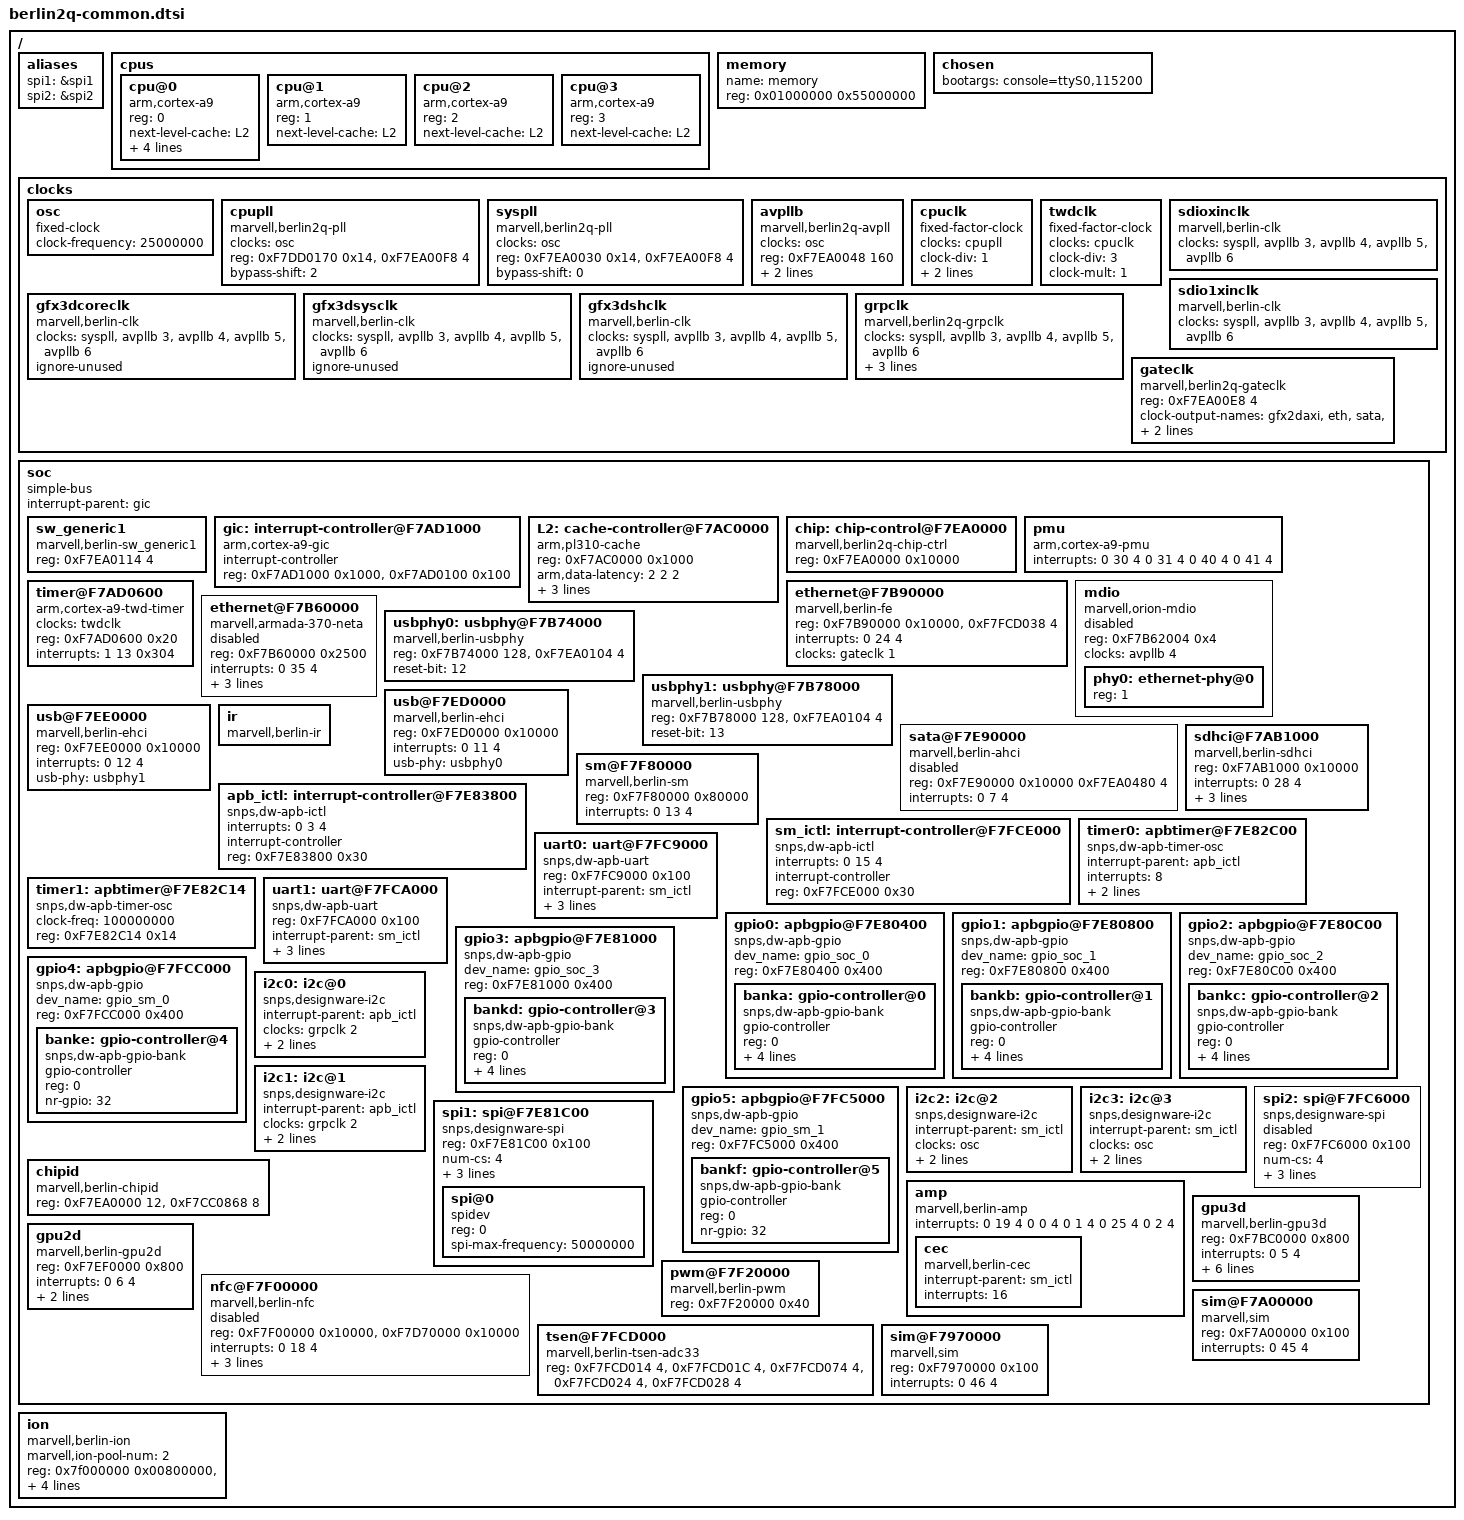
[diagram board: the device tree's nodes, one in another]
/*
 * MARVELL BERLIN2Q SoC device tree source
 *
 * Author:	Jisheng Zhang <jszhang@marvell.com>
 * Copyright (c) 2013 Marvell Technology Group Ltd.
 *		http://www.marvell.com
 *
 * MARVELL BERLIN2Q SoC device nodes are listed in this file.
 * BERLIN2Q based board files can include this file and provide
 * values for board specfic bindings.
 *
 * Note: This file does not include device nodes for all the controllers in
 * BERLIN2Q SoC. As device tree coverage for BERLIN2Q increases,
 * additional nodes can be added to this file.
 *
 * This program is free software; you can redistribute it and/or modify
 * it under the terms of the GNU General Public License version 2 as
 * published by the Free Software Foundation.
*/

/include/ "skeleton.dtsi"

/ {
	aliases {
		spi1 = &spi1;
		spi2 = &spi2;
	};

	cpus {
		#address-cells = <1>;
		#size-cells = <0>;

		cpu@0 {
			device_type = "cpu";
			compatible = "arm,cortex-a9";
			reg = <0>;
			next-level-cache = <&L2>;
			operating-points = <
				/* kHz    uV */
				1200000 1200000
				1000000 1200000
				800000  1200000
				600000  1200000
			>;
			clock-latency = <100000>;
			clocks = <&cpuclk>;
		};

		cpu@1 {
			device_type = "cpu";
			compatible = "arm,cortex-a9";
			reg = <1>;
			next-level-cache = <&L2>;
		};

		cpu@2 {
			device_type = "cpu";
			compatible = "arm,cortex-a9";
			reg = <2>;
			next-level-cache = <&L2>;
		};

		cpu@3 {
			device_type = "cpu";
			compatible = "arm,cortex-a9";
			reg = <3>;
			next-level-cache = <&L2>;
		};
	};

	memory {
		name = "memory";
		device_type = "memory";
		reg = <0x01000000 0x55000000>;
	};

	chosen {
		bootargs = "console=ttyS0,115200";
	};

	clocks {
		#address-cells = <1>;
		#size-cells = <1>;
		ranges;

		osc: osc {
			compatible = "fixed-clock";
			#clock-cells = <0>;
			clock-frequency = <25000000>;
		};

		cpupll: cpupll {
			compatible = "marvell,berlin2q-pll";
			clocks = <&osc>;
			#clock-cells = <0>;
			reg = <0xF7DD0170 0x14>, <0xF7EA00F8 4>;
			bypass-shift = /bits/ 8 <2>;
		};

		syspll: syspll {
			compatible = "marvell,berlin2q-pll";
			clocks = <&osc>;
			#clock-cells = <0>;
			reg = <0xF7EA0030 0x14>, <0xF7EA00F8 4>;
			bypass-shift = /bits/ 8 <0>;
		};

		avpllb: avpllb {
			compatible = "marvell,berlin2q-avpll";
			clocks = <&osc>;
			#clock-cells = <1>;
			reg = <0xF7EA0048 160>;
			clock-output-names = "avpllb1", "avpllb2", "avpllb3", "avpllb4", "avpllb5", "avpllb6", "avpllb7";
		};

		cpuclk: cpuclk {
			compatible = "fixed-factor-clock";
			clocks = <&cpupll>;
			#clock-cells = <0>;
			clock-div = <1>;
			clock-mult = <1>;
			set-rate-parent;
		};

		twdclk: twdclk {
			compatible = "fixed-factor-clock";
			clocks = <&cpuclk>;
			#clock-cells = <0>;
			clock-div = <3>;
			clock-mult = <1>;
		};

		sdioxinclk: sdioxinclk {
			compatible = "marvell,berlin-clk";
			clocks = <&syspll>, <&avpllb 3>, <&avpllb 4>, <&avpllb 5>, <&avpllb 6>;
			#clock-cells = <0>;
		};

		sdio1xinclk: sdio1xinclk {
			compatible = "marvell,berlin-clk";
			clocks = <&syspll>, <&avpllb 3>, <&avpllb 4>, <&avpllb 5>, <&avpllb 6>;
			#clock-cells = <0>;
		};

		gfx3dcoreclk: gfx3dcoreclk {
			compatible = "marvell,berlin-clk";
			clocks = <&syspll>, <&avpllb 3>, <&avpllb 4>, <&avpllb 5>, <&avpllb 6>;
			#clock-cells = <0>;
			ignore-unused;
		};

		gfx3dsysclk: gfx3dsysclk {
			compatible = "marvell,berlin-clk";
			clocks = <&syspll>, <&avpllb 3>, <&avpllb 4>, <&avpllb 5>, <&avpllb 6>;
			#clock-cells = <0>;
			ignore-unused;
		};

		gfx3dshclk: gfx3dshclk {
			compatible = "marvell,berlin-clk";
			clocks = <&syspll>, <&avpllb 3>, <&avpllb 4>, <&avpllb 5>, <&avpllb 6>;
			#clock-cells = <0>;
			ignore-unused;
		};

		grpclk: grpclk {
			compatible = "marvell,berlin2q-grpclk";
			clocks = <&syspll>, <&avpllb 3>, <&avpllb 4>, <&avpllb 5>, <&avpllb 6>;
			#clock-cells = <1>;
			reg = <0xF7EA00F8 4>, <0xF7EA00EC 12>, <0xF7EA00E8 4>;
			clock-output-names = "sys", "drmfigo", "cfg", "gfx2d", "zsp", "perif", "pcube", "vscope", "nfcecc", "app";
		};

		gateclk: gateclk {
			compatible = "marvell,berlin2q-gateclk";
			#clock-cells = <1>;
			reg = <0xF7EA00E8 4>;
			clock-output-names = "gfx2daxi", "eth", "sata", "ahbapb", "usb0", "usb1", "usb2", "usb3", "pbridge", "sdio", "nfc", "pcie", "geth";
		};
	};

	soc {
		#address-cells = <1>;
		#size-cells = <1>;
		compatible = "simple-bus";
		interrupt-parent = <&gic>;
		ranges;

		sw_generic1 {
			compatible = "marvell,berlin-sw_generic1";
			reg = <0xF7EA0114 4>;
		};

		gic:interrupt-controller@F7AD1000 {
			compatible = "arm,cortex-a9-gic";
			#interrupt-cells = <3>;
			interrupt-controller;
			reg = <0xF7AD1000 0x1000>, <0xF7AD0100 0x100>;
		};

		L2: cache-controller@F7AC0000 {
			compatible = "arm,pl310-cache";
			reg = <0xF7AC0000 0x1000>;
			arm,data-latency = <2 2 2>;
			arm,tag-latency = <2 2 2>;
			arm,prefetch-ctrl = <0x70000007>;
			arm,pwr-ctrl = <0x3>;
		};

		chip: chip-control@F7EA0000 {
			compatible = "marvell,berlin2q-chip-ctrl";
			reg = <0xF7EA0000 0x10000>;
			#reset-cells = <3>;
		};

		pmu {
			compatible = "arm,cortex-a9-pmu";
			interrupts = <0 30 4  0 31 4  0 40 4  0 41 4>;
		};

		timer@F7AD0600 {
			compatible = "arm,cortex-a9-twd-timer";
			clocks = <&twdclk>;
			reg = <0xF7AD0600 0x20>;
			interrupts = <1 13 0x304>;
		};

		ethernet@F7B90000 {
			compatible = "marvell,berlin-fe";
			reg = <0xF7B90000 0x10000>,
			      <0xF7FCD038 4>;
			interrupts = <0 24 4>;
			clocks = <&gateclk 1>;
		};

		mdio {
			#address-cells = <1>;
			#size-cells = <0>;
			compatible = "marvell,orion-mdio";
			reg = <0xF7B62004 0x4>;
			status = "disabled";
			clocks = <&avpllb 4>;
			phy0: ethernet-phy@0 {
				reg = <1>;
			};
		};

		ethernet@F7B60000 {
			compatible = "marvell,armada-370-neta";
			reg = <0xF7B60000 0x2500>;
			interrupts = <0 35 4>;
			clocks = <&avpllb 4>;
			status = "disabled";
			phy = <&phy0>;
			phy-mode = "rgmii-id";
		};

		usbphy0: usbphy@F7B74000 {
			compatible = "marvell,berlin-usbphy";
			reg = <0xF7B74000 128>, <0xF7EA0104 4>;
			reset-bit = <12>;
		};

		usbphy1: usbphy@F7B78000 {
			compatible = "marvell,berlin-usbphy";
			reg = <0xF7B78000 128>, <0xF7EA0104 4>;
			reset-bit = <13>;
		};

		usb@F7ED0000 {
			compatible = "marvell,berlin-ehci";
			reg = <0xF7ED0000 0x10000>;
			interrupts = <0 11 4>;
			usb-phy = <&usbphy0>;
		};

		usb@F7EE0000 {
			compatible = "marvell,berlin-ehci";
			reg = <0xF7EE0000 0x10000>;
			interrupts = <0 12 4>;
			usb-phy = <&usbphy1>;
		};

		sata@F7E90000 {
			compatible = "marvell,berlin-ahci";
			reg = <0xF7E90000 0x10000 0xF7EA0480 4>;
			interrupts = <0 7 4>;
			status = "disabled";
		};

		sdhci@F7AB1000 {
			compatible = "marvell,berlin-sdhci";
			reg = <0xF7AB1000 0x10000>;
			interrupts = <0 28 4>;
			clocks = <&grpclk 8>;
			marvell,card-wired;
			marvell,8bit-data;
		};

		sm@F7F80000 {
			compatible = "marvell,berlin-sm";
			reg = <0xF7F80000 0x80000>;
			interrupts = <0 13 4>;
		};

		ir {
			compatible = "marvell,berlin-ir";
		};

		apb_ictl: interrupt-controller@F7E83800 {
			compatible = "snps,dw-apb-ictl";
			interrupts = <0 3 4>;
			interrupt-controller;
			#interrupt-cells = <1>;
			reg = <0xF7E83800 0x30>;
		};

		sm_ictl: interrupt-controller@F7FCE000 {
			compatible = "snps,dw-apb-ictl";
			interrupts = <0 15 4>;
			interrupt-controller;
			#interrupt-cells = <1>;
			reg = <0xF7FCE000 0x30>;
		};

		timer0: apbtimer@F7E82C00 {
			compatible = "snps,dw-apb-timer-osc";
			interrupt-parent = <&apb_ictl>;
			interrupts = <8>;
			clock-freq = <100000000>;
			reg = <0xF7E82C00 0x14>;
		};

		timer1: apbtimer@F7E82C14 {
			compatible = "snps,dw-apb-timer-osc";
			clock-freq = <100000000>;
			reg = <0xF7E82C14 0x14>;
		};

		uart0: uart@F7FC9000 {
			compatible = "snps,dw-apb-uart";
			reg = <0xF7FC9000 0x100>;
			interrupt-parent = <&sm_ictl>;
			interrupts = <8>;
			clock-frequency = <25000000>;
			reg-shift = <2>;
		};

		uart1: uart@F7FCA000 {
			compatible = "snps,dw-apb-uart";
			reg = <0xF7FCA000 0x100>;
			interrupt-parent = <&sm_ictl>;
			interrupts = <9>;
			clock-frequency = <25000000>;
			reg-shift = <2>;
		};

		gpio0: apbgpio@F7E80400 {
			compatible = "snps,dw-apb-gpio";
			dev_name = "gpio_soc_0";
			reg = <0xF7E80400 0x400>;
			#address-cells = <1>;
			#size-cells = <0>;

			banka: gpio-controller@0 {
				compatible = "snps,dw-apb-gpio-bank";
				gpio-controller;
				reg = <0>;
				#gpio-cells = <2>;
				nr-gpio = <32>;
				interrupt-controller;
				#interrupt-cells = <2>;
				interrupt-parent = <&apb_ictl>;
				interrupts = <0>;
			};
		};

		gpio1: apbgpio@F7E80800 {
			compatible = "snps,dw-apb-gpio";
			dev_name = "gpio_soc_1";
			reg = <0xF7E80800 0x400>;
			#address-cells = <1>;
			#size-cells = <0>;

			bankb: gpio-controller@1 {
				compatible = "snps,dw-apb-gpio-bank";
				gpio-controller;
				reg = <0>;
				#gpio-cells = <2>;
				nr-gpio = <32>;
				interrupt-controller;
				#interrupt-cells = <2>;
				interrupt-parent = <&apb_ictl>;
				interrupts = <1>;
			};
		};

		gpio2: apbgpio@F7E80C00 {
			compatible = "snps,dw-apb-gpio";
			dev_name = "gpio_soc_2";
			reg = <0xF7E80C00 0x400>;
			#address-cells = <1>;
			#size-cells = <0>;

			bankc: gpio-controller@2 {
				compatible = "snps,dw-apb-gpio-bank";
				gpio-controller;
				reg = <0>;
				#gpio-cells = <2>;
				nr-gpio = <32>;
				interrupt-controller;
				#interrupt-cells = <2>;
				interrupt-parent = <&apb_ictl>;
				interrupts = <2>;
			};
		};

		gpio3: apbgpio@F7E81000 {
			compatible = "snps,dw-apb-gpio";
			dev_name = "gpio_soc_3";
			reg = <0xF7E81000 0x400>;
			#address-cells = <1>;
			#size-cells = <0>;

			bankd: gpio-controller@3 {
				compatible = "snps,dw-apb-gpio-bank";
				gpio-controller;
				reg = <0>;
				#gpio-cells = <2>;
				nr-gpio = <32>;
				interrupt-controller;
				#interrupt-cells = <2>;
				interrupt-parent = <&apb_ictl>;
				interrupts = <3>;
			};
		};

		gpio4: apbgpio@F7FCC000 {
			compatible = "snps,dw-apb-gpio";
			dev_name = "gpio_sm_0";
			reg = <0xF7FCC000 0x400>;
			#address-cells = <1>;
			#size-cells = <0>;

			banke: gpio-controller@4 {
				compatible = "snps,dw-apb-gpio-bank";
				gpio-controller;
				reg = <0>;
				#gpio-cells = <2>;
				nr-gpio = <32>;
			};
		};

		gpio5: apbgpio@F7FC5000 {
			compatible = "snps,dw-apb-gpio";
			dev_name = "gpio_sm_1";
			reg = <0xF7FC5000 0x400>;
			#address-cells = <1>;
			#size-cells = <0>;

			bankf: gpio-controller@5 {
				compatible = "snps,dw-apb-gpio-bank";
				gpio-controller;
				reg = <0>;
				#gpio-cells = <2>;
				nr-gpio = <32>;
			};
		};

		i2c0: i2c@0 {
			#address-cells = <1>;
			#size-cells = <0>;
			compatible = "snps,designware-i2c";
			interrupt-parent = <&apb_ictl>;
			clocks = <&grpclk 2>;
			reg = <0xF7E81400 0x100>;
			interrupts = <4>;
		};

		i2c1: i2c@1 {
			#address-cells = <1>;
			#size-cells = <0>;
			compatible = "snps,designware-i2c";
			interrupt-parent = <&apb_ictl>;
			clocks = <&grpclk 2>;
			reg = <0xF7E81800 0x100>;
			interrupts = <5>;
		};

		i2c2: i2c@2 {
			#address-cells = <1>;
			#size-cells = <0>;
			compatible = "snps,designware-i2c";
			interrupt-parent = <&sm_ictl>;
			clocks = <&osc>;
			reg = <0XF7FC7000 0x100>;
			interrupts = <6>;
		};

		i2c3: i2c@3 {
			#address-cells = <1>;
			#size-cells = <0>;
			compatible = "snps,designware-i2c";
			interrupt-parent = <&sm_ictl>;
			clocks = <&osc>;
			reg = <0xF7FC8000 0x100>;
			interrupts = <7>;
		};

		spi1: spi@F7E81C00 {
			compatible = "snps,designware-spi";
			reg = <0xF7E81C00 0x100>;
			num-cs = <4>;
			clocks = <&grpclk 2>;
			interrupt-parent = <&apb_ictl>;
			interrupts = <7>;
			#address-cells = <1>;
			#size-cells = <0>;
			spi@0 {
				compatible = "spidev";
				reg = <0>;
				spi-max-frequency = <50000000>;
			};
		};

		spi2: spi@F7FC6000 {
			compatible = "snps,designware-spi";
			reg = <0xF7FC6000 0x100>;
			num-cs = <4>;
			clocks = <&osc>;
			interrupt-parent = <&sm_ictl>;
			interrupts = <5>;
			#address-cells = <1>;
			#size-cells = <0>;
			status = "disabled";
		};

		chipid {
			compatible = "marvell,berlin-chipid";
			reg = <0xF7EA0000 12>, <0xF7CC0868 8>;
		};

		amp {
			compatible = "marvell,berlin-amp";
			interrupts = <0 19 4  0 0 4  0 1 4  0 25 4  0 2 4>;
			cec {
				compatible = "marvell,berlin-cec";
				interrupt-parent = <&sm_ictl>;
				interrupts = <16>;
			};
		};

		gpu3d {
			compatible = "marvell,berlin-gpu3d";
			reg = <0xF7BC0000 0x800>;
			interrupts = <0 5 4>;
			marvell,nonsecure-mem-base = <0>;
			marvell,nonsecure-mem-size = <0x200>;
			marvell,phy-mem-size = <0x80000000>;
			marvell,core-clock-bitfield = <0>;
			marvell,sys-clock-bitfield = <0>;
			marvell,sh-clock-bitfield = <0>;
		};

		gpu2d {
			compatible = "marvell,berlin-gpu2d";
			reg = <0xF7EF0000 0x800>;
			interrupts = <0 6 4>;
			marvell,core-clock-register = <0xF7EA00E8>;
			marvell,core-clock-bitfield = <4>;
		};

		nfc@F7F00000 {
			compatible = "marvell,berlin-nfc";
			reg = <0xF7F00000 0x10000>, <0xF7D70000 0x10000>;
			interrupts = <0 18 4>;
			marvell,nfc-dma;
			marvell,nfc-naked-cmd;
			marvell,nfc-arbi;
			status = "disabled";
		};

		pwm@F7F20000 {
			compatible = "marvell,berlin-pwm";
			reg = <0xF7F20000 0x40>;
		};

		tsen@F7FCD000 {
			compatible = "marvell,berlin-tsen-adc33";
			reg = <0xF7FCD014 4>,
			      <0xF7FCD01C 4>,
			      <0xF7FCD074 4>,
			      <0xF7FCD024 4>,
			      <0xF7FCD028 4>;
		};

		sim@F7A00000 {
			compatible = "marvell,sim";
			reg = <0xF7A00000 0x100>;
			interrupts = <0 45 4>;
		};

		sim@F7970000 {
			compatible = "marvell,sim";
			reg = <0xF7970000 0x100>;
			interrupts = <0 46 4>;
		};
	};

	ion {
		compatible = "marvell,berlin-ion";
		marvell,ion-pool-num = <2>;
		reg = <0x7f000000 0x00800000>, <0x7f800000 0x00800000>;
		reg-names = "video", "audio";
		marvell,ion-attributes-num-per-pool = <2>;
		marvell,ion-pool-attributes = <0x00000002 0x00001000
					0x00000002 0x00001000 >;
	};
};
